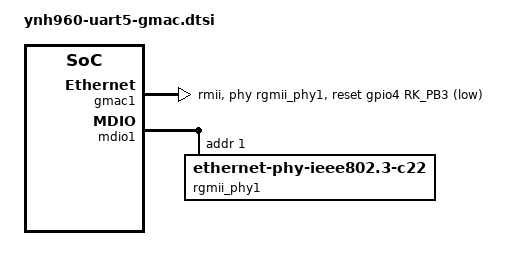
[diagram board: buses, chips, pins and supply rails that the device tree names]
// ynh960: gmac PHY bring-up + free UART5 from EVB PHY reset.
//
// rk3566-evb2 enables &gmac1 as RGMII with:
//   snps,reset-gpio = <&gpio3 RK_PC2 GPIO_ACTIVE_LOW>;  // == UART5_TX_M1
//   phy @ MDIO address 0
// That EVB reset steals UART5_TX (Modbus). RGMII clocks/pinctrl also mismatch
// product HW: with PHY fixed, open still fails ("Failed to reset the dma").
//
// Product wiring matches Innohi siblings / rk3568-evb2 RMII path: RMII + gpio4 PB3
// reset + MDIO reg=1. Stock Android ynh960.dtb uses clock_in_out = "input" with
// SCLK_GMAC1 parented to gmac1_clkin@50M (PHY drives REF_CLK).
//
// Earlier experiment that only flipped clock_in_out to "input" while leaving
// assigned-clock-rates = <0>, <50000000> (SoC still driving SCLK_GMAC1) produced
// ~0.5 Mbps / severe RTP loss. Full input wiring must parent SCLK_GMAC1 to
// &gmac1_clkin and drop the SoC rate assignment (see rk3568-evb2-lp4x-v10.dtsi).

&gmac1_clkin {
	clock-frequency = <50000000>;
};

&gmac1 {
	/delete-property/ snps,reset-gpio;
	/delete-property/ snps,reset-active-low;
	/delete-property/ snps,reset-delays-us;
	/delete-property/ tx_delay;
	/delete-property/ rx_delay;
	/delete-property/ assigned-clock-rates;

	phy-mode = "rmii";
	clock_in_out = "input";

	snps,reset-gpio = <&gpio4 RK_PB3 GPIO_ACTIVE_LOW>;
	snps,reset-active-low;
	/* Reset time is 20ms, 100ms for rtl8211f */
	snps,reset-delays-us = <0 20000 100000>;

	assigned-clocks = <&cru SCLK_GMAC1_RX_TX>, <&cru SCLK_GMAC1>;
	assigned-clock-parents = <&cru SCLK_GMAC1_RMII_SPEED>, <&gmac1_clkin>;

	pinctrl-names = "default";
	pinctrl-0 = <&gmac1m1_miim
		     &gmac1m1_clkinout
		     &gmac1m1_tx_bus2
		     &gmac1m1_rx_bus2
		     &gmac1m1_rx_er>;

	phy-handle = <&rgmii_phy1>;
	status = "okay";
};

&mdio1 {
	/delete-node/ phy@0;

	rgmii_phy1: phy@1 {
		compatible = "ethernet-phy-ieee802.3-c22";
		reg = <0x1>;
	};
};
